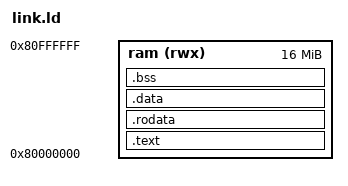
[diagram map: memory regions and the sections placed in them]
OUTPUT_ARCH(riscv)
ENTRY(_start)

MEMORY
{
    ram (rwx) : ORIGIN = 0x80000000, LENGTH = 16M
}

SECTIONS
{
    .text : {
        *(.text.start)
        *(.text*)
    } > ram

    .rodata : {
        *(.rodata*)
    } > ram

    .data : {
        *(.data*)
        *(.sdata*)
    } > ram

    .bss : {
        __bss_start = .;
        *(.bss*)
        *(.sbss*)
        *(COMMON)
        __bss_end = .;
    } > ram

    . = ALIGN(16);
    __stack_top = ORIGIN(ram) + LENGTH(ram);
}
